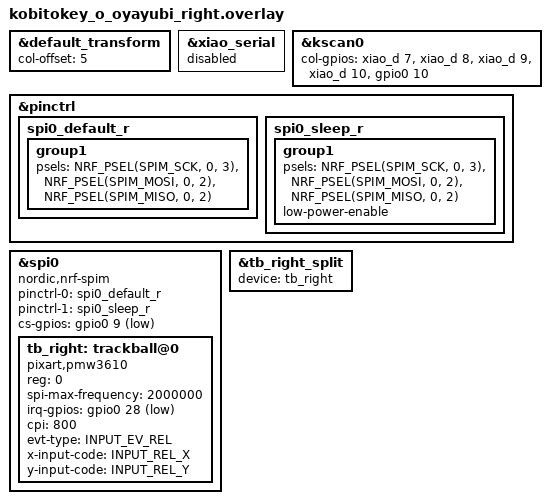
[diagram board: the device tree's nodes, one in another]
#include <zephyr/dt-bindings/pinctrl/nrf-pinctrl.h>
#include <zephyr/dt-bindings/input/input-event-codes.h>
#include "kobitokey_o_oyayubi.dtsi"

/* Right half lands at combined cols 5..9. Natural physical order matches
 * the unified layout (COL0 = inner index = combined col 5). */
&default_transform { col-offset = <5>; };

&xiao_serial { status = "disabled"; };

&kscan0 {
    col-gpios
        = <&xiao_d 7  (GPIO_ACTIVE_HIGH | GPIO_PULL_DOWN)> /* COL0 - P1.12 (D7) (inner) */
        , <&xiao_d 8  (GPIO_ACTIVE_HIGH | GPIO_PULL_DOWN)> /* COL1 - P1.13 (D8) */
        , <&xiao_d 9  (GPIO_ACTIVE_HIGH | GPIO_PULL_DOWN)> /* COL2 - P1.14 (D9) */
        , <&xiao_d 10 (GPIO_ACTIVE_HIGH | GPIO_PULL_DOWN)> /* COL3 - P1.15 (D10) */
        , <&gpio0 10 (GPIO_ACTIVE_HIGH | GPIO_PULL_DOWN)>  /* COL4 - P0.10 NFC2 (pinky) */
        ;
};

&pinctrl {
    spi0_default_r: spi0_default_r {
        group1 {
            psels = <NRF_PSEL(SPIM_SCK,  0, 3)>,
                    <NRF_PSEL(SPIM_MOSI, 0, 2)>,
                    <NRF_PSEL(SPIM_MISO, 0, 2)>;
        };
    };
    spi0_sleep_r: spi0_sleep_r {
        group1 {
            psels = <NRF_PSEL(SPIM_SCK,  0, 3)>,
                    <NRF_PSEL(SPIM_MOSI, 0, 2)>,
                    <NRF_PSEL(SPIM_MISO, 0, 2)>;
            low-power-enable;
        };
    };
};

&spi0 {
    status = "okay";
    compatible = "nordic,nrf-spim";
    pinctrl-0 = <&spi0_default_r>;
    pinctrl-1 = <&spi0_sleep_r>;
    pinctrl-names = "default", "sleep";
    cs-gpios = <&gpio0 9 GPIO_ACTIVE_LOW>;

    tb_right: trackball@0 {
        status = "okay";
        compatible = "pixart,pmw3610";
        reg = <0>;
        spi-max-frequency = <2000000>;
        irq-gpios = <&gpio0 28 (GPIO_ACTIVE_LOW | GPIO_PULL_UP)>;
        cpi = <800>;
        evt-type = <INPUT_EV_REL>;
        x-input-code = <INPUT_REL_X>;
        y-input-code = <INPUT_REL_Y>;
    };
};

&tb_right_split {
    device = <&tb_right>;
};
